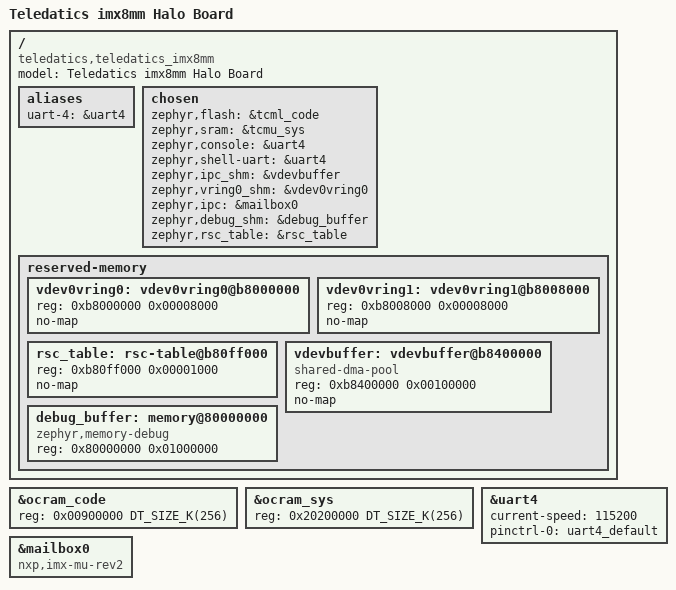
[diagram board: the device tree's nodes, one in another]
/*
 * Copyright (c) 2023, Teledatics, Inc
 *
 * SPDX-License-Identifier: All rights reserved
 */

/dts-v1/;

#include <nxp/nxp_imx8mm_m4.dtsi>

#include "teledatics_imx8mm-pinctrl.dtsi"

/ {
	model = "Teledatics imx8mm Halo Board";
	compatible = "teledatics,teledatics_imx8mm";

	aliases {
		uart-4 = &uart4;
	};

	chosen {
		zephyr,flash = &tcml_code;
		zephyr,sram = &tcmu_sys;
		zephyr,console = &uart4;
		zephyr,shell-uart = &uart4;
		zephyr,ipc_shm = &vdevbuffer;
		zephyr,vring0_shm = &vdev0vring0;
		zephyr,ipc = &mailbox0;
		zephyr,debug_shm = &debug_buffer;
		zephyr,rsc_table = &rsc_table;
	};

	reserved-memory {
		#address-cells = <1>;
		#size-cells = <1>;
		ranges;


		vdev0vring0: vdev0vring0@b8000000 {
			reg = <0xb8000000 0x00008000>;
			no-map;
		};

		vdev0vring1: vdev0vring1@b8008000 {
			reg = <0xb8008000 0x00008000>;
			no-map;
		};

		rsc_table: rsc-table@b80ff000 {
			reg = <0xb80ff000 0x00001000>;
			no-map;
		};

		vdevbuffer: vdevbuffer@b8400000 {
			compatible = "shared-dma-pool";
			reg = <0xb8400000 0x00100000>;
			no-map;
		};

		debug_buffer: memory@80000000 {
			/* DDR RAM allocated to debug output */
			reg = <0x80000000 0x01000000>;			
		};
	};
};

&ocram_code {
	reg = <0x00900000 DT_SIZE_K(256)>;
};

&ocram_sys {
	reg = <0x20200000 DT_SIZE_K(256)>;
};

&uart4 {
	status = "okay";
	current-speed = <115200>;
	pinctrl-0 = <&uart4_default>;
	pinctrl-names = "default";
};

&mailbox0 {
	status = "okay";
	compatible = "nxp,imx-mu-rev2";
};

&debug_buffer {
	status = "okay";
	compatible = "zephyr,memory-debug";
};
